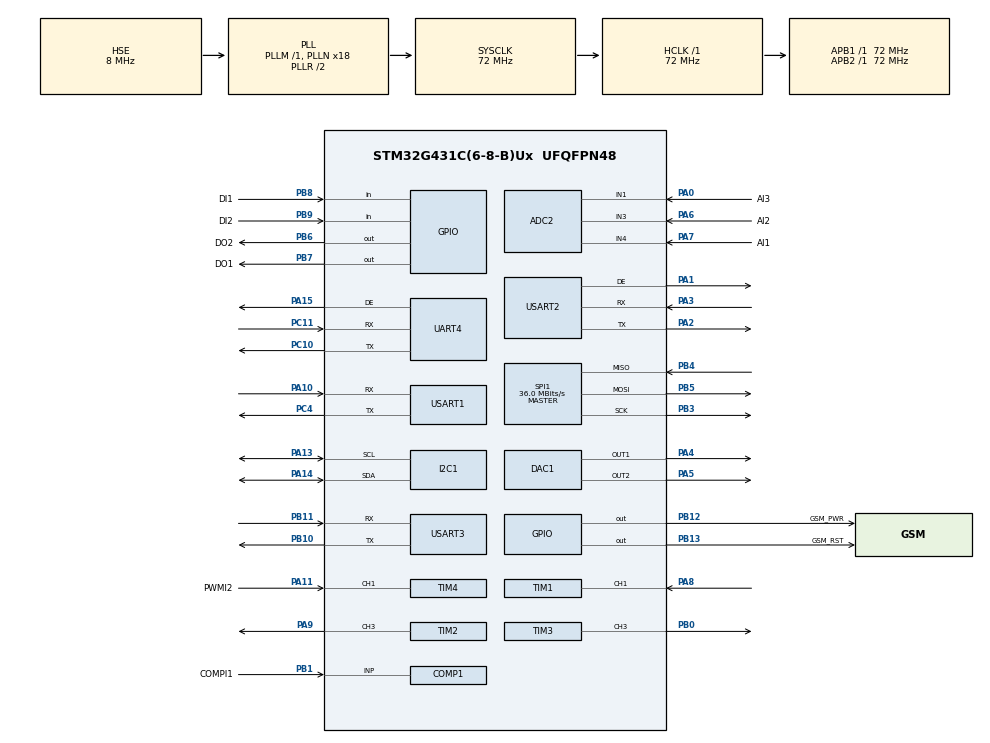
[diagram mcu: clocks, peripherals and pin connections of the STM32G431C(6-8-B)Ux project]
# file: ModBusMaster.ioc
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ADC1.Channel-1\#ChannelRegularConversion=ADC_CHANNEL_VREFINT
ADC1.ClockPrescaler=ADC_CLOCK_SYNC_PCLK_DIV4
ADC1.NbrOfConversion=1
ADC1.NbrOfConversionFlag=1
ADC1.OffsetNumber-1\#ChannelRegularConversion=ADC_OFFSET_NONE
ADC1.Rank-1\#ChannelRegularConversion=1
ADC1.SamplingTime-1\#ChannelRegularConversion=ADC_SAMPLETIME_24CYCLES_5
ADC1.master=1
ADC2.Channel-0\#ChannelRegularConversion=ADC_CHANNEL_1
ADC2.Channel-1\#ChannelRegularConversion=ADC_CHANNEL_4
ADC2.Channel-2\#ChannelRegularConversion=ADC_CHANNEL_3
ADC2.ClockPrescaler=ADC_CLOCK_SYNC_PCLK_DIV4
ADC2.NbrOfConversion=3
ADC2.NbrOfConversionFlag=1
ADC2.OffsetNumber-0\#ChannelRegularConversion=ADC_OFFSET_NONE
ADC2.OffsetNumber-1\#ChannelRegularConversion=ADC_OFFSET_NONE
ADC2.OffsetNumber-2\#ChannelRegularConversion=ADC_OFFSET_NONE
ADC2.Rank-0\#ChannelRegularConversion=1
ADC2.Rank-1\#ChannelRegularConversion=2
ADC2.Rank-2\#ChannelRegularConversion=3
ADC2.SamplingTime-0\#ChannelRegularConversion=ADC_SAMPLETIME_24CYCLES_5
ADC2.SamplingTime-1\#ChannelRegularConversion=ADC_SAMPLETIME_24CYCLES_5
ADC2.SamplingTime-2\#ChannelRegularConversion=ADC_SAMPLETIME_24CYCLES_5
DAC1.DAC_Channel-DAC_OUT2=DAC_CHANNEL_2
I2C1.Timing=0x10C18DCC
Mcu.Family=STM32G4
Mcu.Name=STM32G431C(6-8-B)Ux
Mcu.Package=UFQFPN48
NVIC.PriorityGroup=NVIC_PRIORITYGROUP_4
NVIC.TIM1_CC_IRQn=true\:0\:0\:false\:false\:true\:true\:true\:true
NVIC.TIM1_UP_TIM16_IRQn=true\:0\:0\:false\:false\:true\:true\:true\:true
NVIC.TIM4_IRQn=true\:0\:0\:false\:false\:true\:true\:true\:true
PA0.GPIO_Label=AI3
PA0.Mode=IN1-Single-Ended
PA0.Signal=ADC2_IN1
PA1.Mode=Hardware Flow Control (RS485)
PA1.Signal=USART2_DE
PA10.Mode=Asynchronous
PA10.Signal=USART1_RX
PA11.GPIO_Label=PWMI2
PA11.Signal=S_TIM4_CH1
PA13.Mode=I2C
PA13.Signal=I2C1_SCL
PA14.Mode=I2C
PA14.Signal=I2C1_SDA
PA15.Mode=Hardware Flow Control (RS485)
PA15.Signal=UART4_DE
PA2.Mode=Asynchronous
PA2.Signal=USART2_TX
PA3.Mode=Asynchronous
PA3.Signal=USART2_RX
PA4.Signal=COMP_DAC11_group
PA5.Signal=COMP_DAC12_group
PA6.GPIO_Label=AI2
PA6.Mode=IN3-Single-Ended
PA6.Signal=ADC2_IN3
PA7.GPIO_Label=AI1
PA7.Mode=IN4-Single-Ended
PA7.Signal=ADC2_IN4
PA8.Signal=S_TIM1_CH1
PA9.Signal=S_TIM2_CH3
PB0.Signal=S_TIM3_CH3
PB1.GPIO_Label=COMPI1
PB1.Mode=INP
PB1.Signal=COMP1_INP
PB10.Mode=Asynchronous
PB10.Signal=USART3_TX
PB11.Mode=Asynchronous
PB11.Signal=USART3_RX
PB12.GPIO_Label=GSM_PWR
PB12.GPIO_PuPd=GPIO_PULLDOWN
PB12.Signal=GPIO_Output
PB13.GPIO_Label=GSM_RST
PB13.GPIO_PuPd=GPIO_PULLDOWN
PB13.Signal=GPIO_Output
PB3.Mode=Full_Duplex_Master
PB3.Signal=SPI1_SCK
PB4.Mode=Full_Duplex_Master
PB4.Signal=SPI1_MISO
PB5.Mode=Full_Duplex_Master
PB5.Signal=SPI1_MOSI
PB6.GPIO_Label=DO2
PB6.Signal=GPIO_Output
PB7.GPIO_Label=DO1
PB7.Signal=GPIO_Output
PB8-BOOT0.GPIO_Label=DI1
PB8-BOOT0.Signal=GPIO_Input
PB9.GPIO_Label=DI2
PB9.Signal=GPIO_Input
PC10.Mode=Asynchronous
PC10.Signal=UART4_TX
PC11.Mode=Asynchronous
PC11.Signal=UART4_RX
PC14-OSC32_IN.Mode=LSE-External-Oscillator
PC14-OSC32_IN.Signal=RCC_OSC32_IN
PC15-OSC32_OUT.Mode=LSE-External-Oscillator
PC15-OSC32_OUT.Signal=RCC_OSC32_OUT
PC4.Mode=Asynchronous
PC4.Signal=USART1_TX
PF0-OSC_IN.Mode=HSE-External-Oscillator
PF0-OSC_IN.Signal=RCC_OSC_IN
PF1-OSC_OUT.Mode=HSE-External-Oscillator
PF1-OSC_OUT.Signal=RCC_OSC_OUT
ProjectManager.HeapSize=0x200
ProjectManager.StackSize=0x400
ProjectManager.TargetToolchain=STM32CubeIDE
RCC.ADC12Freq_Value=72000000
RCC.AHBFreq_Value=72000000
RCC.APB1Freq_Value=72000000
RCC.APB1TimFreq_Value=72000000
RCC.APB2Freq_Value=72000000
RCC.APB2TimFreq_Value=72000000
RCC.CortexFreq_Value=72000000
RCC.EXTERNAL_CLOCK_VALUE=12288000
RCC.HCLKFreq_Value=72000000
RCC.HSE_VALUE=8000000
RCC.HSI48_VALUE=48000000
RCC.HSI_VALUE=16000000
RCC.PLLN=18
RCC.PLLSourceVirtual=RCC_PLLSOURCE_HSE
RCC.SYSCLKFreq_VALUE=72000000
RCC.SYSCLKSource=RCC_SYSCLKSOURCE_PLLCLK
RCC.USBFreq_Value=72000000
RCC.VCOOutputFreq_Value=144000000
SH.COMP_DAC11_group.0=DAC1_OUT1,DAC_OUT1
SH.COMP_DAC12_group.0=DAC1_OUT2,DAC_OUT2
SH.S_TIM1_CH1.0=TIM1_CH1,PWM_Input_1
SH.S_TIM2_CH3.0=TIM2_CH3,PWM Generation3 CH3
SH.S_TIM3_CH3.0=TIM3_CH3,PWM Generation3 CH3
SH.S_TIM4_CH1.0=TIM4_CH1,PWM_Input_1
SPI1.CalculateBaudRate=36.0 MBits/s
SPI1.Direction=SPI_DIRECTION_2LINES
SPI1.Mode=SPI_MODE_MASTER
SPI1.VirtualType=VM_MASTER
TIM1.Prescaler=72-1
TIM2.AutoReloadPreload=TIM_AUTORELOAD_PRELOAD_ENABLE
TIM2.Channel-PWM\ Generation3\ CH3=TIM_CHANNEL_3
TIM2.PeriodNoDither=100-1
TIM2.Prescaler=72-1
TIM3.AutoReloadPreload=TIM_AUTORELOAD_PRELOAD_ENABLE
TIM3.Channel-PWM\ Generation3\ CH3=TIM_CHANNEL_3
TIM3.Prescaler=72-1
USART1.VirtualMode-Asynchronous=VM_ASYNC
USART2.VirtualMode-Asynchronous=VM_ASYNC
USART2.VirtualMode-Hardware\ Flow\ Control\ (RS485)=VM_ASYNC
USART3.VirtualMode-Asynchronous=VM_ASYNC
VP_ADC1_Vref_Input.Mode=IN-Vrefint
VP_COMP1_VS_VREFINT.Mode=VREFINT
VP_IWDG_VS_IWDG.Mode=IWDG_Activate
VP_RTC_VS_RTC_Activate.Mode=RTC_Enabled
VP_SYS_VS_DBSignals.Mode=DisableDeadBatterySignals
VP_TIM1_VS_ClockSourceINT.Mode=Internal
VP_TIM2_VS_ClockSourceINT.Mode=Internal
VP_TIM3_VS_ClockSourceINT.Mode=Internal
VP_TIM4_VS_ClockSourceINT.Mode=Internal
board=custom

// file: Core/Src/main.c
/* USER CODE BEGIN Header */
/**
  ******************************************************************************
  * @file           : main.c
  * @brief          : Main program body
  ******************************************************************************
  * @attention
  *
  * Copyright (c) 2025 STMicroelectronics.
  * All rights reserved.
  *
  * This software is licensed under terms that can be found in the LICENSE file
  * in the root directory of this software component.
  * If no LICENSE file comes with this software, it is provided AS-IS.
  *
  ******************************************************************************
  */
/* USER CODE END Header */
#include "main.h"

/* USER CODE BEGIN Includes */
#include "ReadAction.h"
/* USER CODE END Includes */

ADC_HandleTypeDef hadc1;
ADC_HandleTypeDef hadc2;

COMP_HandleTypeDef hcomp1;

DAC_HandleTypeDef hdac1;

I2C_HandleTypeDef hi2c1;

IWDG_HandleTypeDef hiwdg;

RTC_HandleTypeDef hrtc;

SPI_HandleTypeDef hspi1;

TIM_HandleTypeDef htim1;
TIM_HandleTypeDef htim2;
TIM_HandleTypeDef htim3;
TIM_HandleTypeDef htim4;

UART_HandleTypeDef huart4;
UART_HandleTypeDef huart1;
UART_HandleTypeDef huart2;
UART_HandleTypeDef huart3;

/* USER CODE BEGIN PV */
DataPar DataVar;
/* USER CODE END PV */

void SystemClock_Config(void);
static void MX_GPIO_Init(void);
static void MX_IWDG_Init(void);
static void MX_RTC_Init(void);
static void MX_ADC1_Init(void);
static void MX_USART1_UART_Init(void);
static void MX_ADC2_Init(void);
static void MX_DAC1_Init(void);
static void MX_I2C1_Init(void);
static void MX_SPI1_Init(void);
static void MX_TIM2_Init(void);
static void MX_TIM3_Init(void);
static void MX_UART4_Init(void);
static void MX_USART3_UART_Init(void);
static void MX_TIM4_Init(void);
static void MX_TIM1_Init(void);
static void MX_COMP1_Init(void);
static void MX_USART2_UART_Init(void);

/* USER CODE BEGIN 0 */
/**
  * @brief CallBack function of UART
  * @param pointer UART_HandleTypeDef
  * @retval non
  */
void HAL_UART_RxCpltCallback(UART_HandleTypeDef *huart)
{
    if (huart->Instance == USART3) // Check which UART is receiving data
    {
    	AT_UART_RxCpltCallback();
    }
}
/* USER CODE END 0 */

int main(void)
{

  /* MCU Configuration--------------------------------------------------------*/

  /* Reset of all peripherals, Initializes the Flash interface and the Systick. */
  HAL_Init();

  /* Configure the system clock */
  SystemClock_Config();

  /* Initialize all configured peripherals */
  MX_GPIO_Init();
  MX_IWDG_Init();
  MX_RTC_Init();
  MX_ADC1_Init();
  MX_USART1_UART_Init();
  MX_ADC2_Init();
  MX_DAC1_Init();
  MX_I2C1_Init();
  MX_SPI1_Init();
  MX_TIM2_Init();
  MX_TIM3_Init();
  MX_UART4_Init();
  MX_USART3_UART_Init();
  MX_TIM4_Init();
  MX_TIM1_Init();
  MX_COMP1_Init();
  MX_USART2_UART_Init();
  /* USER CODE BEGIN 2 */
  HAL_Delay(1500);

  /* USER CODE END 2 */

  /* Infinite loop */
  while (1)
  {

  }
}

void SystemClock_Config(void)
{
  RCC_OscInitTypeDef RCC_OscInitStruct = {0};
  RCC_ClkInitTypeDef RCC_ClkInitStruct = {0};

  /** Configure the main internal regulator output voltage
  */
  HAL_PWREx_ControlVoltageScaling(PWR_REGULATOR_VOLTAGE_SCALE1);

  /** Initializes the RCC Oscillators according to the specified parameters
  * in the RCC_OscInitTypeDef structure.
  */
  RCC_OscInitStruct.OscillatorType = RCC_OSCILLATORTYPE_LSI|RCC_OSCILLATORTYPE_HSE;
  RCC_OscInitStruct.HSEState = RCC_HSE_ON;
  RCC_OscInitStruct.LSIState = RCC_LSI_ON;
  RCC_OscInitStruct.PLL.PLLState = RCC_PLL_ON;
  RCC_OscInitStruct.PLL.PLLSource = RCC_PLLSOURCE_HSE;
  RCC_OscInitStruct.PLL.PLLM = RCC_PLLM_DIV1;
  RCC_OscInitStruct.PLL.PLLN = 18;
  RCC_OscInitStruct.PLL.PLLP = RCC_PLLP_DIV2;
  RCC_OscInitStruct.PLL.PLLQ = RCC_PLLQ_DIV2;
  RCC_OscInitStruct.PLL.PLLR = RCC_PLLR_DIV2;
  if (HAL_RCC_OscConfig(&RCC_OscInitStruct) != HAL_OK)
  {
    Error_Handler();
  }

  /** Initializes the CPU, AHB and APB buses clocks
  */
  RCC_ClkInitStruct.ClockType = RCC_CLOCKTYPE_HCLK|RCC_CLOCKTYPE_SYSCLK
                              |RCC_CLOCKTYPE_PCLK1|RCC_CLOCKTYPE_PCLK2;
  RCC_ClkInitStruct.SYSCLKSource = RCC_SYSCLKSOURCE_PLLCLK;
  RCC_ClkInitStruct.AHBCLKDivider = RCC_SYSCLK_DIV1;
  RCC_ClkInitStruct.APB1CLKDivider = RCC_HCLK_DIV1;
  RCC_ClkInitStruct.APB2CLKDivider = RCC_HCLK_DIV1;

  if (HAL_RCC_ClockConfig(&RCC_ClkInitStruct, FLASH_LATENCY_2) != HAL_OK)
  {
    Error_Handler();
  }
}

static void MX_ADC1_Init(void)
{

  ADC_MultiModeTypeDef multimode = {0};
  ADC_ChannelConfTypeDef sConfig = {0};

  /** Common config
  */
  hadc1.Instance = ADC1;
  hadc1.Init.ClockPrescaler = ADC_CLOCK_SYNC_PCLK_DIV4;
  hadc1.Init.Resolution = ADC_RESOLUTION_12B;
  hadc1.Init.DataAlign = ADC_DATAALIGN_RIGHT;
  hadc1.Init.GainCompensation = 0;
  hadc1.Init.ScanConvMode = ADC_SCAN_DISABLE;
  hadc1.Init.EOCSelection = ADC_EOC_SINGLE_CONV;
  hadc1.Init.LowPowerAutoWait = DISABLE;
  hadc1.Init.ContinuousConvMode = DISABLE;
  hadc1.Init.NbrOfConversion = 1;
  hadc1.Init.DiscontinuousConvMode = DISABLE;
  hadc1.Init.ExternalTrigConv = ADC_SOFTWARE_START;
  hadc1.Init.ExternalTrigConvEdge = ADC_EXTERNALTRIGCONVEDGE_NONE;
  hadc1.Init.DMAContinuousRequests = DISABLE;
  hadc1.Init.Overrun = ADC_OVR_DATA_PRESERVED;
  hadc1.Init.OversamplingMode = DISABLE;
  if (HAL_ADC_Init(&hadc1) != HAL_OK)
  {
    Error_Handler();
  }

  /** Configure the ADC multi-mode
  */
  multimode.Mode = ADC_MODE_INDEPENDENT;
  if (HAL_ADCEx_MultiModeConfigChannel(&hadc1, &multimode) != HAL_OK)
  {
    Error_Handler();
  }

  /** Configure Regular Channel
  */
  sConfig.Channel = ADC_CHANNEL_VREFINT;
  sConfig.Rank = ADC_REGULAR_RANK_1;
  sConfig.SamplingTime = ADC_SAMPLETIME_24CYCLES_5;
  sConfig.SingleDiff = ADC_SINGLE_ENDED;
  sConfig.OffsetNumber = ADC_OFFSET_NONE;
  sConfig.Offset = 0;
  if (HAL_ADC_ConfigChannel(&hadc1, &sConfig) != HAL_OK)
  {
    Error_Handler();
  }

}

static void MX_ADC2_Init(void)
{

  ADC_ChannelConfTypeDef sConfig = {0};

  /** Common config
  */
  hadc2.Instance = ADC2;
  hadc2.Init.ClockPrescaler = ADC_CLOCK_SYNC_PCLK_DIV4;
  hadc2.Init.Resolution = ADC_RESOLUTION_12B;
  hadc2.Init.DataAlign = ADC_DATAALIGN_RIGHT;
  hadc2.Init.GainCompensation = 0;
  hadc2.Init.ScanConvMode = ADC_SCAN_ENABLE;
  hadc2.Init.EOCSelection = ADC_EOC_SINGLE_CONV;
  hadc2.Init.LowPowerAutoWait = DISABLE;
  hadc2.Init.ContinuousConvMode = DISABLE;
  hadc2.Init.NbrOfConversion = 3;
  hadc2.Init.DiscontinuousConvMode = DISABLE;
  hadc2.Init.ExternalTrigConv = ADC_SOFTWARE_START;
  hadc2.Init.ExternalTrigConvEdge = ADC_EXTERNALTRIGCONVEDGE_NONE;
  hadc2.Init.DMAContinuousRequests = DISABLE;
  hadc2.Init.Overrun = ADC_OVR_DATA_PRESERVED;
  hadc2.Init.OversamplingMode = DISABLE;
  if (HAL_ADC_Init(&hadc2) != HAL_OK)
  {
    Error_Handler();
  }

  /** Configure Regular Channel
  */
  sConfig.Channel = ADC_CHANNEL_1;
  sConfig.Rank = ADC_REGULAR_RANK_1;
  sConfig.SamplingTime = ADC_SAMPLETIME_24CYCLES_5;
  sConfig.SingleDiff = ADC_SINGLE_ENDED;
  sConfig.OffsetNumber = ADC_OFFSET_NONE;
  sConfig.Offset = 0;
  if (HAL_ADC_ConfigChannel(&hadc2, &sConfig) != HAL_OK)
  {
    Error_Handler();
  }

  /** Configure Regular Channel
  */
  sConfig.Channel = ADC_CHANNEL_4;
  sConfig.Rank = ADC_REGULAR_RANK_2;
  if (HAL_ADC_ConfigChannel(&hadc2, &sConfig) != HAL_OK)
  {
    Error_Handler();
  }

  /** Configure Regular Channel
  */
  sConfig.Channel = ADC_CHANNEL_3;
  sConfig.Rank = ADC_REGULAR_RANK_3;
  if (HAL_ADC_ConfigChannel(&hadc2, &sConfig) != HAL_OK)
  {
    Error_Handler();
  }

}

static void MX_COMP1_Init(void)
{

  hcomp1.Instance = COMP1;
  hcomp1.Init.InputPlus = COMP_INPUT_PLUS_IO2;
  hcomp1.Init.InputMinus = COMP_INPUT_MINUS_VREFINT;
  hcomp1.Init.OutputPol = COMP_OUTPUTPOL_NONINVERTED;
  hcomp1.Init.Hysteresis = COMP_HYSTERESIS_NONE;
  hcomp1.Init.BlankingSrce = COMP_BLANKINGSRC_NONE;
  hcomp1.Init.TriggerMode = COMP_TRIGGERMODE_NONE;
  if (HAL_COMP_Init(&hcomp1) != HAL_OK)
  {
    Error_Handler();
  }

}

static void MX_DAC1_Init(void)
{

  DAC_ChannelConfTypeDef sConfig = {0};

  /** DAC Initialization
  */
  hdac1.Instance = DAC1;
  if (HAL_DAC_Init(&hdac1) != HAL_OK)
  {
    Error_Handler();
  }

  /** DAC channel OUT1 config
  */
  sConfig.DAC_HighFrequency = DAC_HIGH_FREQUENCY_INTERFACE_MODE_AUTOMATIC;
  sConfig.DAC_DMADoubleDataMode = DISABLE;
  sConfig.DAC_SignedFormat = DISABLE;
  sConfig.DAC_SampleAndHold = DAC_SAMPLEANDHOLD_DISABLE;
  sConfig.DAC_Trigger = DAC_TRIGGER_NONE;
  sConfig.DAC_Trigger2 = DAC_TRIGGER_NONE;
  sConfig.DAC_OutputBuffer = DAC_OUTPUTBUFFER_ENABLE;
  sConfig.DAC_ConnectOnChipPeripheral = DAC_CHIPCONNECT_EXTERNAL;
  sConfig.DAC_UserTrimming = DAC_TRIMMING_FACTORY;
  if (HAL_DAC_ConfigChannel(&hdac1, &sConfig, DAC_CHANNEL_1) != HAL_OK)
  {
    Error_Handler();
  }

  /** DAC channel OUT2 config
  */
  if (HAL_DAC_ConfigChannel(&hdac1, &sConfig, DAC_CHANNEL_2) != HAL_OK)
  {
    Error_Handler();
  }
  /* USER CODE BEGIN DAC1_Init 2 */
  HAL_DAC_Start(&hdac1, DAC_CHANNEL_1);
  HAL_DAC_Start(&hdac1, DAC_CHANNEL_2);
  /* USER CODE END DAC1_Init 2 */

}

static void MX_I2C1_Init(void)
{

  hi2c1.Instance = I2C1;
  hi2c1.Init.Timing = 0x10C18DCC;
  hi2c1.Init.OwnAddress1 = 0;
  hi2c1.Init.AddressingMode = I2C_ADDRESSINGMODE_7BIT;
  hi2c1.Init.DualAddressMode = I2C_DUALADDRESS_DISABLE;
  hi2c1.Init.OwnAddress2 = 0;
  hi2c1.Init.OwnAddress2Masks = I2C_OA2_NOMASK;
  hi2c1.Init.GeneralCallMode = I2C_GENERALCALL_DISABLE;
  hi2c1.Init.NoStretchMode = I2C_NOSTRETCH_DISABLE;
  if (HAL_I2C_Init(&hi2c1) != HAL_OK)
  {
    Error_Handler();
  }

  /** Configure Analogue filter
  */
  if (HAL_I2CEx_ConfigAnalogFilter(&hi2c1, I2C_ANALOGFILTER_ENABLE) != HAL_OK)
  {
    Error_Handler();
  }

  /** Configure Digital filter
  */
  if (HAL_I2CEx_ConfigDigitalFilter(&hi2c1, 0) != HAL_OK)
  {
    Error_Handler();
  }

}

static void MX_IWDG_Init(void)
{

  hiwdg.Instance = IWDG;
  hiwdg.Init.Prescaler = IWDG_PRESCALER_4;
  hiwdg.Init.Window = 4095;
  hiwdg.Init.Reload = 4095;
  if (HAL_IWDG_Init(&hiwdg) != HAL_OK)
  {
    Error_Handler();
  }

}

static void MX_RTC_Init(void)
{

  /** Initialize RTC Only
  */
  hrtc.Instance = RTC;
  hrtc.Init.HourFormat = RTC_HOURFORMAT_24;
  hrtc.Init.AsynchPrediv = 127;
  hrtc.Init.SynchPrediv = 255;
  hrtc.Init.OutPut = RTC_OUTPUT_DISABLE;
  hrtc.Init.OutPutRemap = RTC_OUTPUT_REMAP_NONE;
  hrtc.Init.OutPutPolarity = RTC_OUTPUT_POLARITY_HIGH;
  hrtc.Init.OutPutType = RTC_OUTPUT_TYPE_OPENDRAIN;
  hrtc.Init.OutPutPullUp = RTC_OUTPUT_PULLUP_NONE;
  if (HAL_RTC_Init(&hrtc) != HAL_OK)
  {
    Error_Handler();
  }

}

static void MX_SPI1_Init(void)
{

  /* SPI1 parameter configuration*/
  hspi1.Instance = SPI1;
  hspi1.Init.Mode = SPI_MODE_MASTER;
  hspi1.Init.Direction = SPI_DIRECTION_2LINES;
  hspi1.Init.DataSize = SPI_DATASIZE_4BIT;
  hspi1.Init.CLKPolarity = SPI_POLARITY_LOW;
  hspi1.Init.CLKPhase = SPI_PHASE_1EDGE;
  hspi1.Init.NSS = SPI_NSS_SOFT;
  hspi1.Init.BaudRatePrescaler = SPI_BAUDRATEPRESCALER_2;
  hspi1.Init.FirstBit = SPI_FIRSTBIT_MSB;
  hspi1.Init.TIMode = SPI_TIMODE_DISABLE;
  hspi1.Init.CRCCalculation = SPI_CRCCALCULATION_DISABLE;
  hspi1.Init.CRCPolynomial = 7;
  hspi1.Init.CRCLength = SPI_CRC_LENGTH_DATASIZE;
  hspi1.Init.NSSPMode = SPI_NSS_PULSE_ENABLE;
  if (HAL_SPI_Init(&hspi1) != HAL_OK)
  {
    Error_Handler();
  }

}

static void MX_TIM1_Init(void)
{

  TIM_ClockConfigTypeDef sClockSourceConfig = {0};
  TIM_SlaveConfigTypeDef sSlaveConfig = {0};
  TIM_IC_InitTypeDef sConfigIC = {0};
  TIM_MasterConfigTypeDef sMasterConfig = {0};

  htim1.Instance = TIM1;
  htim1.Init.Prescaler = 72-1;
  htim1.Init.CounterMode = TIM_COUNTERMODE_UP;
  htim1.Init.Period = 65535;
  htim1.Init.ClockDivision = TIM_CLOCKDIVISION_DIV1;
  htim1.Init.RepetitionCounter = 0;
  htim1.Init.AutoReloadPreload = TIM_AUTORELOAD_PRELOAD_DISABLE;
  if (HAL_TIM_Base_Init(&htim1) != HAL_OK)
  {
    Error_Handler();
  }
  sClockSourceConfig.ClockSource = TIM_CLOCKSOURCE_INTERNAL;
  if (HAL_TIM_ConfigClockSource(&htim1, &sClockSourceConfig) != HAL_OK)
  {
    Error_Handler();
  }
  if (HAL_TIM_IC_Init(&htim1) != HAL_OK)
  {
    Error_Handler();
  }
  sSlaveConfig.SlaveMode = TIM_SLAVEMODE_RESET;
  sSlaveConfig.InputTrigger = TIM_TS_TI1FP1;
  sSlaveConfig.TriggerPolarity = TIM_INPUTCHANNELPOLARITY_RISING;
  sSlaveConfig.TriggerPrescaler = TIM_ICPSC_DIV1;
  sSlaveConfig.TriggerFilter = 0;
  if (HAL_TIM_SlaveConfigSynchro(&htim1, &sSlaveConfig) != HAL_OK)
  {
    Error_Handler();
  }
  sConfigIC.ICPolarity = TIM_INPUTCHANNELPOLARITY_RISING;
  sConfigIC.ICSelection = TIM_ICSELECTION_DIRECTTI;
  sConfigIC.ICPrescaler = TIM_ICPSC_DIV1;
  sConfigIC.ICFilter = 0;
  if (HAL_TIM_IC_ConfigChannel(&htim1, &sConfigIC, TIM_CHANNEL_1) != HAL_OK)
  {
    Error_Handler();
  }
  sConfigIC.ICPolarity = TIM_INPUTCHANNELPOLARITY_FALLING;
  sConfigIC.ICSelection = TIM_ICSELECTION_INDIRECTTI;
  if (HAL_TIM_IC_ConfigChannel(&htim1, &sConfigIC, TIM_CHANNEL_2) != HAL_OK)
  {
    Error_Handler();
  }
  sMasterConfig.MasterOutputTrigger = TIM_TRGO_RESET;
  sMasterConfig.MasterOutputTrigger2 = TIM_TRGO2_RESET;
  sMasterConfig.MasterSlaveMode = TIM_MASTERSLAVEMODE_DISABLE;
  if (HAL_TIMEx_MasterConfigSynchronization(&htim1, &sMasterConfig) != HAL_OK)
  {
    Error_Handler();
  }

}

static void MX_TIM2_Init(void)
{

  TIM_ClockConfigTypeDef sClockSourceConfig = {0};
  TIM_MasterConfigTypeDef sMasterConfig = {0};
  TIM_OC_InitTypeDef sConfigOC = {0};

  htim2.Instance = TIM2;
  htim2.Init.Prescaler = 72-1;
  htim2.Init.CounterMode = TIM_COUNTERMODE_UP;
  htim2.Init.Period = 99;
  htim2.Init.ClockDivision = TIM_CLOCKDIVISION_DIV1;
  htim2.Init.AutoReloadPreload = TIM_AUTORELOAD_PRELOAD_ENABLE;
  if (HAL_TIM_Base_Init(&htim2) != HAL_OK)
  {
    Error_Handler();
  }
  sClockSourceConfig.ClockSource = TIM_CLOCKSOURCE_INTERNAL;
  if (HAL_TIM_ConfigClockSource(&htim2, &sClockSourceConfig) != HAL_OK)
  {
    Error_Handler();
  }
  if (HAL_TIM_PWM_Init(&htim2) != HAL_OK)
  {
    Error_Handler();
  }
  sMasterConfig.MasterOutputTrigger = TIM_TRGO_RESET;
  sMasterConfig.MasterSlaveMode = TIM_MASTERSLAVEMODE_DISABLE;
  if (HAL_TIMEx_MasterConfigSynchronization(&htim2, &sMasterConfig) != HAL_OK)
  {
    Error_Handler();
  }
  sConfigOC.OCMode = TIM_OCMODE_PWM1;
  sConfigOC.Pulse = 0;
  sConfigOC.OCPolarity = TIM_OCPOLARITY_HIGH;
  sConfigOC.OCFastMode = TIM_OCFAST_DISABLE;
  if (HAL_TIM_PWM_ConfigChannel(&htim2, &sConfigOC, TIM_CHANNEL_3) != HAL_OK)
  {
    Error_Handler();
  }
  HAL_TIM_MspPostInit(&htim2);

}

static void MX_TIM3_Init(void)
{

  TIM_ClockConfigTypeDef sClockSourceConfig = {0};
  TIM_MasterConfigTypeDef sMasterConfig = {0};
  TIM_OC_InitTypeDef sConfigOC = {0};

  htim3.Instance = TIM3;
  htim3.Init.Prescaler = 72-1;
  htim3.Init.CounterMode = TIM_COUNTERMODE_UP;
  htim3.Init.Period = 65535;
  htim3.Init.ClockDivision = TIM_CLOCKDIVISION_DIV1;
  htim3.Init.AutoReloadPreload = TIM_AUTORELOAD_PRELOAD_ENABLE;
  if (HAL_TIM_Base_Init(&htim3) != HAL_OK)
  {
    Error_Handler();
  }
  sClockSourceConfig.ClockSource = TIM_CLOCKSOURCE_INTERNAL;
  if (HAL_TIM_ConfigClockSource(&htim3, &sClockSourceConfig) != HAL_OK)
  {
    Error_Handler();
  }
  if (HAL_TIM_PWM_Init(&htim3) != HAL_OK)
  {
    Error_Handler();
  }
  sMasterConfig.MasterOutputTrigger = TIM_TRGO_RESET;
  sMasterConfig.MasterSlaveMode = TIM_MASTERSLAVEMODE_DISABLE;
  if (HAL_TIMEx_MasterConfigSynchronization(&htim3, &sMasterConfig) != HAL_OK)
  {
    Error_Handler();
  }
  sConfigOC.OCMode = TIM_OCMODE_PWM1;
  sConfigOC.Pulse = 0;
  sConfigOC.OCPolarity = TIM_OCPOLARITY_HIGH;
  sConfigOC.OCFastMode = TIM_OCFAST_DISABLE;
  if (HAL_TIM_PWM_ConfigChannel(&htim3, &sConfigOC, TIM_CHANNEL_3) != HAL_OK)
  {
    Error_Handler();
  }
  HAL_TIM_MspPostInit(&htim3);

}

static void MX_TIM4_Init(void)
{

  TIM_ClockConfigTypeDef sClockSourceConfig = {0};
  TIM_SlaveConfigTypeDef sSlaveConfig = {0};
  TIM_IC_InitTypeDef sConfigIC = {0};
  TIM_MasterConfigTypeDef sMasterConfig = {0};

  htim4.Instance = TIM4;
  htim4.Init.Prescaler = 0;
  htim4.Init.CounterMode = TIM_COUNTERMODE_UP;
  htim4.Init.Period = 65535;
  htim4.Init.ClockDivision = TIM_CLOCKDIVISION_DIV1;
  htim4.Init.AutoReloadPreload = TIM_AUTORELOAD_PRELOAD_DISABLE;
  if (HAL_TIM_Base_Init(&htim4) != HAL_OK)
  {
    Error_Handler();
  }
  sClockSourceConfig.ClockSource = TIM_CLOCKSOURCE_INTERNAL;
  if (HAL_TIM_ConfigClockSource(&htim4, &sClockSourceConfig) != HAL_OK)
  {
    Error_Handler();
  }
  if (HAL_TIM_IC_Init(&htim4) != HAL_OK)
  {
    Error_Handler();
  }
  sSlaveConfig.SlaveMode = TIM_SLAVEMODE_RESET;
  sSlaveConfig.InputTrigger = TIM_TS_TI1FP1;
  sSlaveConfig.TriggerPolarity = TIM_INPUTCHANNELPOLARITY_RISING;
  sSlaveConfig.TriggerPrescaler = TIM_ICPSC_DIV1;
  sSlaveConfig.TriggerFilter = 0;
  if (HAL_TIM_SlaveConfigSynchro(&htim4, &sSlaveConfig) != HAL_OK)
  {
    Error_Handler();
  }
  sConfigIC.ICPolarity = TIM_INPUTCHANNELPOLARITY_RISING;
  sConfigIC.ICSelection = TIM_ICSELECTION_DIRECTTI;
  sConfigIC.ICPrescaler = TIM_ICPSC_DIV1;
  sConfigIC.ICFilter = 0;
  if (HAL_TIM_IC_ConfigChannel(&htim4, &sConfigIC, TIM_CHANNEL_1) != HAL_OK)
  {
    Error_Handler();
  }
  sConfigIC.ICPolarity = TIM_INPUTCHANNELPOLARITY_FALLING;
  sConfigIC.ICSelection = TIM_ICSELECTION_INDIRECTTI;
  if (HAL_TIM_IC_ConfigChannel(&htim4, &sConfigIC, TIM_CHANNEL_2) != HAL_OK)
  {
    Error_Handler();
  }
  sMasterConfig.MasterOutputTrigger = TIM_TRGO_RESET;
  sMasterConfig.MasterSlaveMode = TIM_MASTERSLAVEMODE_DISABLE;
  if (HAL_TIMEx_MasterConfigSynchronization(&htim4, &sMasterConfig) != HAL_OK)
  {
    Error_Handler();
  }

}

static void MX_UART4_Init(void)
{

  huart4.Instance = UART4;
  huart4.Init.BaudRate = 115200;
  huart4.Init.WordLength = UART_WORDLENGTH_8B;
  huart4.Init.StopBits = UART_STOPBITS_1;
  huart4.Init.Parity = UART_PARITY_NONE;
  huart4.Init.Mode = UART_MODE_TX_RX;
  huart4.Init.HwFlowCtl = UART_HWCONTROL_NONE;
  huart4.Init.OverSampling = UART_OVERSAMPLING_16;
  huart4.Init.OneBitSampling = UART_ONE_BIT_SAMPLE_DISABLE;
  huart4.Init.ClockPrescaler = UART_PRESCALER_DIV1;
  huart4.AdvancedInit.AdvFeatureInit = UART_ADVFEATURE_NO_INIT;
  if (HAL_RS485Ex_Init(&huart4, UART_DE_POLARITY_HIGH, 0, 0) != HAL_OK)
  {
    Error_Handler();
  }
  if (HAL_UARTEx_SetTxFifoThreshold(&huart4, UART_TXFIFO_THRESHOLD_1_8) != HAL_OK)
  {
    Error_Handler();
  }
  if (HAL_UARTEx_SetRxFifoThreshold(&huart4, UART_RXFIFO_THRESHOLD_1_8) != HAL_OK)
  {
    Error_Handler();
  }
  if (HAL_UARTEx_DisableFifoMode(&huart4) != HAL_OK)
  {
    Error_Handler();
  }

}

static void MX_USART1_UART_Init(void)
{

  huart1.Instance = USART1;
  huart1.Init.BaudRate = 115200;
  huart1.Init.WordLength = UART_WORDLENGTH_8B;
  huart1.Init.StopBits = UART_STOPBITS_1;
  huart1.Init.Parity = UART_PARITY_NONE;
  huart1.Init.Mode = UART_MODE_TX_RX;
  huart1.Init.HwFlowCtl = UART_HWCONTROL_NONE;
  huart1.Init.OverSampling = UART_OVERSAMPLING_16;
  huart1.Init.OneBitSampling = UART_ONE_BIT_SAMPLE_DISABLE;
  huart1.Init.ClockPrescaler = UART_PRESCALER_DIV1;
  huart1.AdvancedInit.AdvFeatureInit = UART_ADVFEATURE_NO_INIT;
  if (HAL_UART_Init(&huart1) != HAL_OK)
  {
    Error_Handler();
  }
  if (HAL_UARTEx_SetTxFifoThreshold(&huart1, UART_TXFIFO_THRESHOLD_1_8) != HAL_OK)
  {
    Error_Handler();
  }
  if (HAL_UARTEx_SetRxFifoThreshold(&huart1, UART_RXFIFO_THRESHOLD_1_8) != HAL_OK)
  {
    Error_Handler();
  }
  if (HAL_UARTEx_DisableFifoMode(&huart1) != HAL_OK)
  {
    Error_Handler();
  }

}

static void MX_USART2_UART_Init(void)
{

  huart2.Instance = USART2;
  huart2.Init.BaudRate = 115200;
  huart2.Init.WordLength = UART_WORDLENGTH_8B;
  huart2.Init.StopBits = UART_STOPBITS_1;
  huart2.Init.Parity = UART_PARITY_NONE;
  huart2.Init.Mode = UART_MODE_TX_RX;
  huart2.Init.HwFlowCtl = UART_HWCONTROL_NONE;
  huart2.Init.OverSampling = UART_OVERSAMPLING_16;
  huart2.Init.OneBitSampling = UART_ONE_BIT_SAMPLE_DISABLE;
  huart2.Init.ClockPrescaler = UART_PRESCALER_DIV1;
  huart2.AdvancedInit.AdvFeatureInit = UART_ADVFEATURE_NO_INIT;
  if (HAL_RS485Ex_Init(&huart2, UART_DE_POLARITY_HIGH, 0, 0) != HAL_OK)
  {
    Error_Handler();
  }
  if (HAL_UARTEx_SetTxFifoThreshold(&huart2, UART_TXFIFO_THRESHOLD_1_8) != HAL_OK)
  {
    Error_Handler();
  }
  if (HAL_UARTEx_SetRxFifoThreshold(&huart2, UART_RXFIFO_THRESHOLD_1_8) != HAL_OK)
  {
    Error_Handler();
  }
  if (HAL_UARTEx_DisableFifoMode(&huart2) != HAL_OK)
  {
    Error_Handler();
  }

}

static void MX_USART3_UART_Init(void)
{

  huart3.Instance = USART3;
  huart3.Init.BaudRate = 115200;
  huart3.Init.WordLength = UART_WORDLENGTH_8B;
  huart3.Init.StopBits = UART_STOPBITS_1;
  huart3.Init.Parity = UART_PARITY_NONE;
  huart3.Init.Mode = UART_MODE_TX_RX;
  huart3.Init.HwFlowCtl = UART_HWCONTROL_NONE;
  huart3.Init.OverSampling = UART_OVERSAMPLING_16;
  huart3.Init.OneBitSampling = UART_ONE_BIT_SAMPLE_DISABLE;
  huart3.Init.ClockPrescaler = UART_PRESCALER_DIV1;
  huart3.AdvancedInit.AdvFeatureInit = UART_ADVFEATURE_NO_INIT;
  if (HAL_UART_Init(&huart3) != HAL_OK)
  {
    Error_Handler();
  }
  if (HAL_UARTEx_SetTxFifoThreshold(&huart3, UART_TXFIFO_THRESHOLD_1_8) != HAL_OK)
  {
    Error_Handler();
  }
  if (HAL_UARTEx_SetRxFifoThreshold(&huart3, UART_RXFIFO_THRESHOLD_1_8) != HAL_OK)
  {
    Error_Handler();
  }
  if (HAL_UARTEx_DisableFifoMode(&huart3) != HAL_OK)
  {
    Error_Handler();
  }

}

static void MX_GPIO_Init(void)
{
  GPIO_InitTypeDef GPIO_InitStruct = {0};

  /* GPIO Ports Clock Enable */
  __HAL_RCC_GPIOC_CLK_ENABLE();
  __HAL_RCC_GPIOF_CLK_ENABLE();
  __HAL_RCC_GPIOA_CLK_ENABLE();
  __HAL_RCC_GPIOB_CLK_ENABLE();

  /*Configure GPIO pin Output Level */
  HAL_GPIO_WritePin(GPIOB, GSM_PWR_Pin|GSM_RST_Pin|DO2_Pin|DO1_Pin, GPIO_PIN_RESET);

  /*Configure GPIO pins : GSM_PWR_Pin GSM_RST_Pin */
  GPIO_InitStruct.Pin = GSM_PWR_Pin|GSM_RST_Pin;
  GPIO_InitStruct.Mode = GPIO_MODE_OUTPUT_PP;
  GPIO_InitStruct.Pull = GPIO_PULLDOWN;
  GPIO_InitStruct.Speed = GPIO_SPEED_FREQ_LOW;
  HAL_GPIO_Init(GPIOB, &GPIO_InitStruct);

  /*Configure GPIO pins : DO2_Pin DO1_Pin */
  GPIO_InitStruct.Pin = DO2_Pin|DO1_Pin;
  GPIO_InitStruct.Mode = GPIO_MODE_OUTPUT_PP;
  GPIO_InitStruct.Pull = GPIO_NOPULL;
  GPIO_InitStruct.Speed = GPIO_SPEED_FREQ_LOW;
  HAL_GPIO_Init(GPIOB, &GPIO_InitStruct);

  /*Configure GPIO pins : DI1_Pin DI2_Pin */
  GPIO_InitStruct.Pin = DI1_Pin|DI2_Pin;
  GPIO_InitStruct.Mode = GPIO_MODE_INPUT;
  GPIO_InitStruct.Pull = GPIO_NOPULL;
  HAL_GPIO_Init(GPIOB, &GPIO_InitStruct);

}

/* USER CODE BEGIN 4 */
PUTCHAR_PROTOTYPE
{
  HAL_UART_Transmit(&huart1, (uint8_t *)&ch, 1, 1000);
  return ch;
}
/* USER CODE END 4 */

void Error_Handler(void)
{
  __disable_irq();
  while (1)
  {
  }
}
